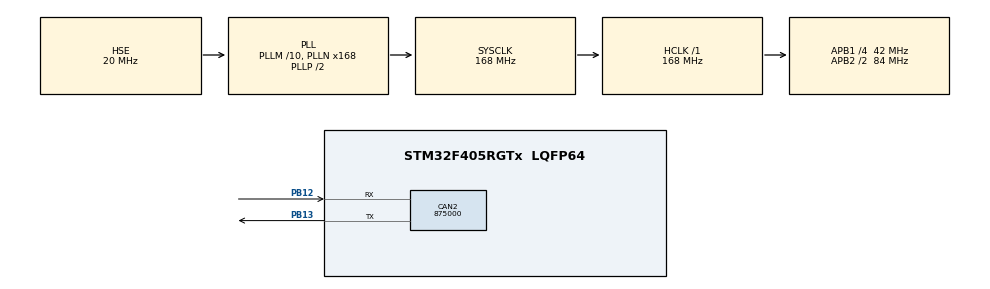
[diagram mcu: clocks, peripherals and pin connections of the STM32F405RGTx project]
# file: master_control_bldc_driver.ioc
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CAN2.CalculateBaudRate=875000
CAN2.CalculateTimeBit=1142
CAN2.CalculateTimeQuantum=380.95238095238096
FREERTOS.Tasks01=defaultTask,24,128,StartDefaultTask,Default,NULL,Dynamic,NULL,NULL
Mcu.Family=STM32F4
Mcu.Name=STM32F405RGTx
Mcu.Package=LQFP64
NVIC.PriorityGroup=NVIC_PRIORITYGROUP_4
NVIC.TIM1_UP_TIM10_IRQn=true\:15\:0\:false\:false\:true\:false\:false\:true\:true
NVIC.TimeBase=TIM1_UP_TIM10_IRQn
NVIC.TimeBaseIP=TIM10
PA13.Mode=Serial_Wire
PA13.Signal=SYS_JTMS-SWDIO
PA14.Mode=Serial_Wire
PA14.Signal=SYS_JTCK-SWCLK
PB12.Mode=CAN_Activate
PB12.Signal=CAN2_RX
PB13.Mode=CAN_Activate
PB13.Signal=CAN2_TX
PH0-OSC_IN.Mode=HSE-External-Oscillator
PH0-OSC_IN.Signal=RCC_OSC_IN
PH1-OSC_OUT.Mode=HSE-External-Oscillator
PH1-OSC_OUT.Signal=RCC_OSC_OUT
ProjectManager.HeapSize=0x200
ProjectManager.StackSize=0x400
ProjectManager.TargetToolchain=Makefile
RCC.48MHZClocksFreq_Value=84000000
RCC.AHBFreq_Value=168000000
RCC.APB1CLKDivider=RCC_HCLK_DIV4
RCC.APB1Freq_Value=42000000
RCC.APB1TimFreq_Value=84000000
RCC.APB2CLKDivider=RCC_HCLK_DIV2
RCC.APB2Freq_Value=84000000
RCC.APB2TimFreq_Value=168000000
RCC.CortexFreq_Value=168000000
RCC.HCLKFreq_Value=168000000
RCC.HSE_VALUE=20000000
RCC.HSI_VALUE=16000000
RCC.LSE_VALUE=32768
RCC.PLLM=10
RCC.PLLN=168
RCC.PLLSourceVirtual=RCC_PLLSOURCE_HSE
RCC.SYSCLKFreq_VALUE=168000000
RCC.SYSCLKSource=RCC_SYSCLKSOURCE_PLLCLK
RCC.VCOOutputFreq_Value=336000000
VP_FREERTOS_VS_CMSIS_V2.Mode=CMSIS_V2
VP_SYS_VS_tim10.Mode=TIM10
board=custom

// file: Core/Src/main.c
/* USER CODE BEGIN Header */
/**
  ******************************************************************************
  * @file           : main.c
  * @brief          : Main program body
  ******************************************************************************
  * @attention
  *
  * Copyright (c) 2026 STMicroelectronics.
  * All rights reserved.
  *
  * This software is licensed under terms that can be found in the LICENSE file
  * in the root directory of this software component.
  * If no LICENSE file comes with this software, it is provided AS-IS.
  *
  ******************************************************************************
  */
/* USER CODE END Header */
#include "main.h"
#include "cmsis_os.h"

/* USER CODE BEGIN Includes */
#include "can.h"
#include "math_ops.h"
/* USER CODE END Includes */

/* USER CODE BEGIN PD */
#define RAD_TO_DEG(rad) 	((rad) * 57.29577951308232f)  // 180/π
#define DEG_TO_RAD(deg) 	((deg) * 0.017453292519943f)  // π/180

#define RPM_TO_RADS(rpm)	((rpm) * 0.1047197551f)				// 2π/60
#define RADS_TO_RPM(rads)	((rads)* 9.549296586f)				// 60/2π

/* USER CODE END PD */

CAN_HandleTypeDef hcan2;

/* Definitions for defaultTask */
osThreadId_t defaultTaskHandle;
const osThreadAttr_t defaultTask_attributes = {
  .name = "defaultTask",
  .stack_size = 256 * 4,
  .priority = (osPriority_t) osPriorityNormal,
};

osThreadId_t Task1Handle;
const osThreadAttr_t Task1_attributes = {
  .name = "Task1",
  .stack_size = 256 * 4,
  .priority = (osPriority_t) osPriorityNormal,
};
/* USER CODE BEGIN PV */

/* can setup*/
CANTxMessage can_tx;
CANRxMessage can_rx;
JointCommand_t joint_cmd;
JointState_t joint_state;

JointRobot_t motorID_1;
JointRobot_t motorID_2;
JointRobot_t motorID_3;
JointRobot_t motorID_4;
JointRobot_t motorID_5;

/* USER CODE END PV */

void SystemClock_Config(void);
static void MX_GPIO_Init(void);

void StartDefaultTask(void *argument);
void Task1(void *argument);
/* USER CODE BEGIN PFP */
  float anpha = 0.0f;
float f = 1.0f;           // Tần số dao động của động cơ (VD: 1 Hz)
float dt = 0.005f;        // Chu kỳ vòng lặp 5ms (osDelay(5))
// float delta = 2.0f * M_PI * f * dt; // Bước nhảy của góc sau mỗi 5ms

float speed = 10000.0f;             // Tốc độ mong muốn (VD: 100 độ/giây)
// float delta_pos = speed * dt;     // Lượng góc tăng/giảm mỗi 5ms (0.5 độ)

float current_pos = 0.0f;         // Góc hiện tại
float max_pos = 1500.0f;           // Góc tối đa
float min_pos = -1500.0f;             // Góc tối thiểu
int8_t direction = 1;             // Chiều quay: 1 (tăng), -1 (giảm)
/* USER CODE END PFP */

int main(void)
{

  /* MCU Configuration--------------------------------------------------------*/

  /* Reset of all peripherals, Initializes the Flash interface and the Systick. */
  HAL_Init();

  /* Configure the system clock */
  SystemClock_Config();

  /* Initialize all configured peripherals */
  MX_GPIO_Init();
  MX_CAN2_Init();
  /* USER CODE BEGIN 2 */

  /*CAN setup   */
  can_rx_init(&can_rx);
  can_tx_init(&can_tx);
  HAL_CAN_Start(&hcan2);
  HAL_CAN_ActivateNotification(&hcan2, CAN_IT_RX_FIFO0_MSG_PENDING);

  /* USER CODE END 2 */

  /* Init scheduler */
  osKernelInitialize();

  /* Create the thread(s) */
  /* creation of defaultTask */
  defaultTaskHandle = osThreadNew(StartDefaultTask, NULL, &defaultTask_attributes);
  Task1Handle = osThreadNew(Task1, NULL, &Task1_attributes);

  /* Start scheduler */
  osKernelStart();

  /* We should never get here as control is now taken by the scheduler */

  /* Infinite loop */
  while (1)
  {

  }
}

void SystemClock_Config(void)
{
  RCC_OscInitTypeDef RCC_OscInitStruct = {0};
  RCC_ClkInitTypeDef RCC_ClkInitStruct = {0};

  /** Configure the main internal regulator output voltage
  */
  __HAL_RCC_PWR_CLK_ENABLE();
  __HAL_PWR_VOLTAGESCALING_CONFIG(PWR_REGULATOR_VOLTAGE_SCALE1);

  /** Initializes the RCC Oscillators according to the specified parameters
  * in the RCC_OscInitTypeDef structure.
  */
  RCC_OscInitStruct.OscillatorType = RCC_OSCILLATORTYPE_HSE;
  RCC_OscInitStruct.HSEState = RCC_HSE_ON;
  RCC_OscInitStruct.PLL.PLLState = RCC_PLL_ON;
  RCC_OscInitStruct.PLL.PLLSource = RCC_PLLSOURCE_HSE;
  RCC_OscInitStruct.PLL.PLLM = 10;
  RCC_OscInitStruct.PLL.PLLN = 168;
  RCC_OscInitStruct.PLL.PLLP = RCC_PLLP_DIV2;
  RCC_OscInitStruct.PLL.PLLQ = 4;
  if (HAL_RCC_OscConfig(&RCC_OscInitStruct) != HAL_OK)
  {
    Error_Handler();
  }

  /** Initializes the CPU, AHB and APB buses clocks
  */
  RCC_ClkInitStruct.ClockType = RCC_CLOCKTYPE_HCLK|RCC_CLOCKTYPE_SYSCLK
                              |RCC_CLOCKTYPE_PCLK1|RCC_CLOCKTYPE_PCLK2;
  RCC_ClkInitStruct.SYSCLKSource = RCC_SYSCLKSOURCE_PLLCLK;
  RCC_ClkInitStruct.AHBCLKDivider = RCC_SYSCLK_DIV1;
  RCC_ClkInitStruct.APB1CLKDivider = RCC_HCLK_DIV4;
  RCC_ClkInitStruct.APB2CLKDivider = RCC_HCLK_DIV2;

  if (HAL_RCC_ClockConfig(&RCC_ClkInitStruct, FLASH_LATENCY_5) != HAL_OK)
  {
    Error_Handler();
  }
}

static void MX_GPIO_Init(void)
{

  /* GPIO Ports Clock Enable */
  __HAL_RCC_GPIOH_CLK_ENABLE();
  __HAL_RCC_GPIOB_CLK_ENABLE();
  __HAL_RCC_GPIOA_CLK_ENABLE();

}

/* USER CODE BEGIN 4 */
void HAL_CAN_RxFifo0MsgPendingCallback(CAN_HandleTypeDef *hcan)
{
  if (hcan->Instance == CAN2)
  {
    while (HAL_CAN_GetRxFifoFillLevel(hcan, CAN_RX_FIFO0) > 0)
    {
      if (HAL_CAN_GetRxMessage(hcan, CAN_RX_FIFO0, &can_rx.rx_header, can_rx.data) == HAL_OK)
      {
        switch (can_rx.rx_header.StdId){
          case 0x02:
            Master_Unpack_State_2(&can_rx, &motorID_1.state);
            break;

          case 0x03:
            Master_Unpack_State_2(&can_rx, &motorID_2.state);
            break;

          case 0x04:
            Master_Unpack_State_2(&can_rx, &motorID_3.state);
            break;

          case 0x05:
            Master_Unpack_State_2(&can_rx, &motorID_4.state);
            break;
          case 0x06:
            Master_Unpack_State_2(&can_rx, &motorID_5.state);
            break;

          default:
            break;
        }
      }
    }

  }
}

void Task1(void *argument)
{
  /* USER CODE BEGIN 5 */
  uint32_t TxMailbox;
  osDelay(1000);

  /* Infinite loop */
  for(;;)
  {

    DataCmdJoint(&motorID_1.cmd, DEG_TO_RAD(-45),RPM_TO_RADS(10),0);
    MasterSendData_2(&hcan2, &can_tx, &motorID_1.cmd);
    osDelay(1000);
    DataCmdJoint(&motorID_1.cmd, DEG_TO_RAD(45),RPM_TO_RADS(-10),0);
    MasterSendData_2(&hcan2, &can_tx, &motorID_1.cmd);
    osDelay(1000);
    DataCmdJoint(&motorID_1.cmd, DEG_TO_RAD(-90),RPM_TO_RADS(50),0);
    MasterSendData_2(&hcan2, &can_tx, &motorID_1.cmd);
    osDelay(1000);
    DataCmdJoint(&motorID_1.cmd, DEG_TO_RAD(90),RPM_TO_RADS(-50),0);
    MasterSendData_2(&hcan2, &can_tx, &motorID_1.cmd);
    osDelay(1000);

    DataCmdJoint(&motorID_1.cmd, DEG_TO_RAD(-270),RPM_TO_RADS(300),0);
    MasterSendData_2(&hcan2, &can_tx, &motorID_1.cmd);
    osDelay(1000);
    DataCmdJoint(&motorID_1.cmd, DEG_TO_RAD(270),RPM_TO_RADS(-300),0);
    MasterSendData_2(&hcan2, &can_tx, &motorID_1.cmd);
    osDelay(1000);
    DataCmdJoint(&motorID_1.cmd, DEG_TO_RAD(-360),RPM_TO_RADS(1000),0);
    MasterSendData_2(&hcan2, &can_tx, &motorID_1.cmd);
    osDelay(1000);
    DataCmdJoint(&motorID_1.cmd, DEG_TO_RAD(360),RPM_TO_RADS(-1000),0);
    MasterSendData_2(&hcan2, &can_tx, &motorID_1.cmd);
    osDelay(1000);

    DataCmdJoint(&motorID_1.cmd, DEG_TO_RAD(0),RPM_TO_RADS(1700),0);
    MasterSendData_2(&hcan2, &can_tx, &motorID_1.cmd);
    osDelay(1000);
    DataCmdJoint(&motorID_1.cmd, DEG_TO_RAD(180),RPM_TO_RADS(-1700),0);
    MasterSendData_2(&hcan2, &can_tx, &motorID_1.cmd);
    osDelay(1000);
    DataCmdJoint(&motorID_1.cmd, DEG_TO_RAD(360),RPM_TO_RADS(2700),0);
    MasterSendData_2(&hcan2, &can_tx, &motorID_1.cmd);
    osDelay(1000);
    DataCmdJoint(&motorID_1.cmd, DEG_TO_RAD(360),RPM_TO_RADS(2700),0);
    MasterSendData_2(&hcan2, &can_tx, &motorID_1.cmd);
    osDelay(1000);

  }

  /* USER CODE END 5 */
}

void testCan(){
  // uint32_t TxMailbox;

  // DataCmdJoint(&motorID_1.cmd, DEG_TO_RAD(0),RPM_TO_RADS(10),0);
  // MasterSendData(&hcan2, &can_tx, &motorID_1.cmd);
  // osDelay(500);
  // DataCmdJoint(&motorID_1.cmd, DEG_TO_RAD(180),RPM_TO_RADS(10),0);
  // MasterSendData(&hcan2, &can_tx, &motorID_1.cmd);
  // osDelay(500);
  // DataCmdJoint(&motorID_1.cmd, DEG_TO_RAD(360),RPM_TO_RADS(10),0);
  // MasterSendData(&hcan2, &can_tx, &motorID_1.cmd);
}
/* USER CODE END 4 */

void StartDefaultTask(void *argument)
{
  /* USER CODE BEGIN 5 */
  uint32_t TxMailbox;

  motorID_1.cmd.can_id = 0x02;
  motorID_2.cmd.can_id = 0x03;
  motorID_3.cmd.can_id = 0x04;
  motorID_4.cmd.can_id = 0x05;
  motorID_5.cmd.can_id = 0x06;

float delta = 2.0f * M_PI * f * dt; // Bước nhảy của góc sau mỗi 5ms

float delta_pos = speed * dt;

  /* Infinite loop */
  for(;;)
  {

    DataCmdJoint(&motorID_4.cmd, motorID_5.state.p_act, motorID_5.state.v_act, 0);
    MasterSendData_2(&hcan2, &can_tx, &motorID_4.cmd);

    DataCmdJoint(&motorID_5.cmd, motorID_4.state.p_act, motorID_4.state.v_act, 0);
    MasterSendData_2(&hcan2, &can_tx, &motorID_5.cmd);

    DataCmdJoint(&motorID_2.cmd, DEG_TO_RAD(360*sinf(anpha)), RPM_TO_RADS(360*sinf(anpha)), 0);
    MasterSendData_2(&hcan2, &can_tx, &motorID_2.cmd);

    anpha += delta;

    if(anpha >= (2.0f * M_PI))
    {
      anpha -= (2.0f * M_PI);
    }
// ==============================
    // 1. Tính toán vị trí mới
    // current_pos += direction * delta_pos;

    // // 2. Kiểm tra giới hạn để đảo chiều (Tạo quỹ đạo hình tam giác)
    // if (current_pos >= max_pos)
    // {
    //   current_pos = max_pos;
    //   direction = -1; // Đảo chiều quay ngược lại
    // }
    // else if (current_pos <= min_pos)
    // {
    //   current_pos = min_pos;
    //   direction = 1;  // Đảo chiều quay tiến lên
    // }
    // DataCmdJoint(&motorID_3.cmd, DEG_TO_RAD(current_pos), RPM_TO_RADS(360*sinf(anpha)), 0);
    // MasterSendData_2(&hcan2, &can_tx, &motorID_3.cmd);
// ==============================

    osDelay(5);
  }

  /* USER CODE END 5 */
}

void HAL_TIM_PeriodElapsedCallback(TIM_HandleTypeDef *htim)
{
  if (htim->Instance == TIM10)
  {
    HAL_IncTick();
  }
}

void Error_Handler(void)
{
  __disable_irq();
  while (1)
  {
  }
}
